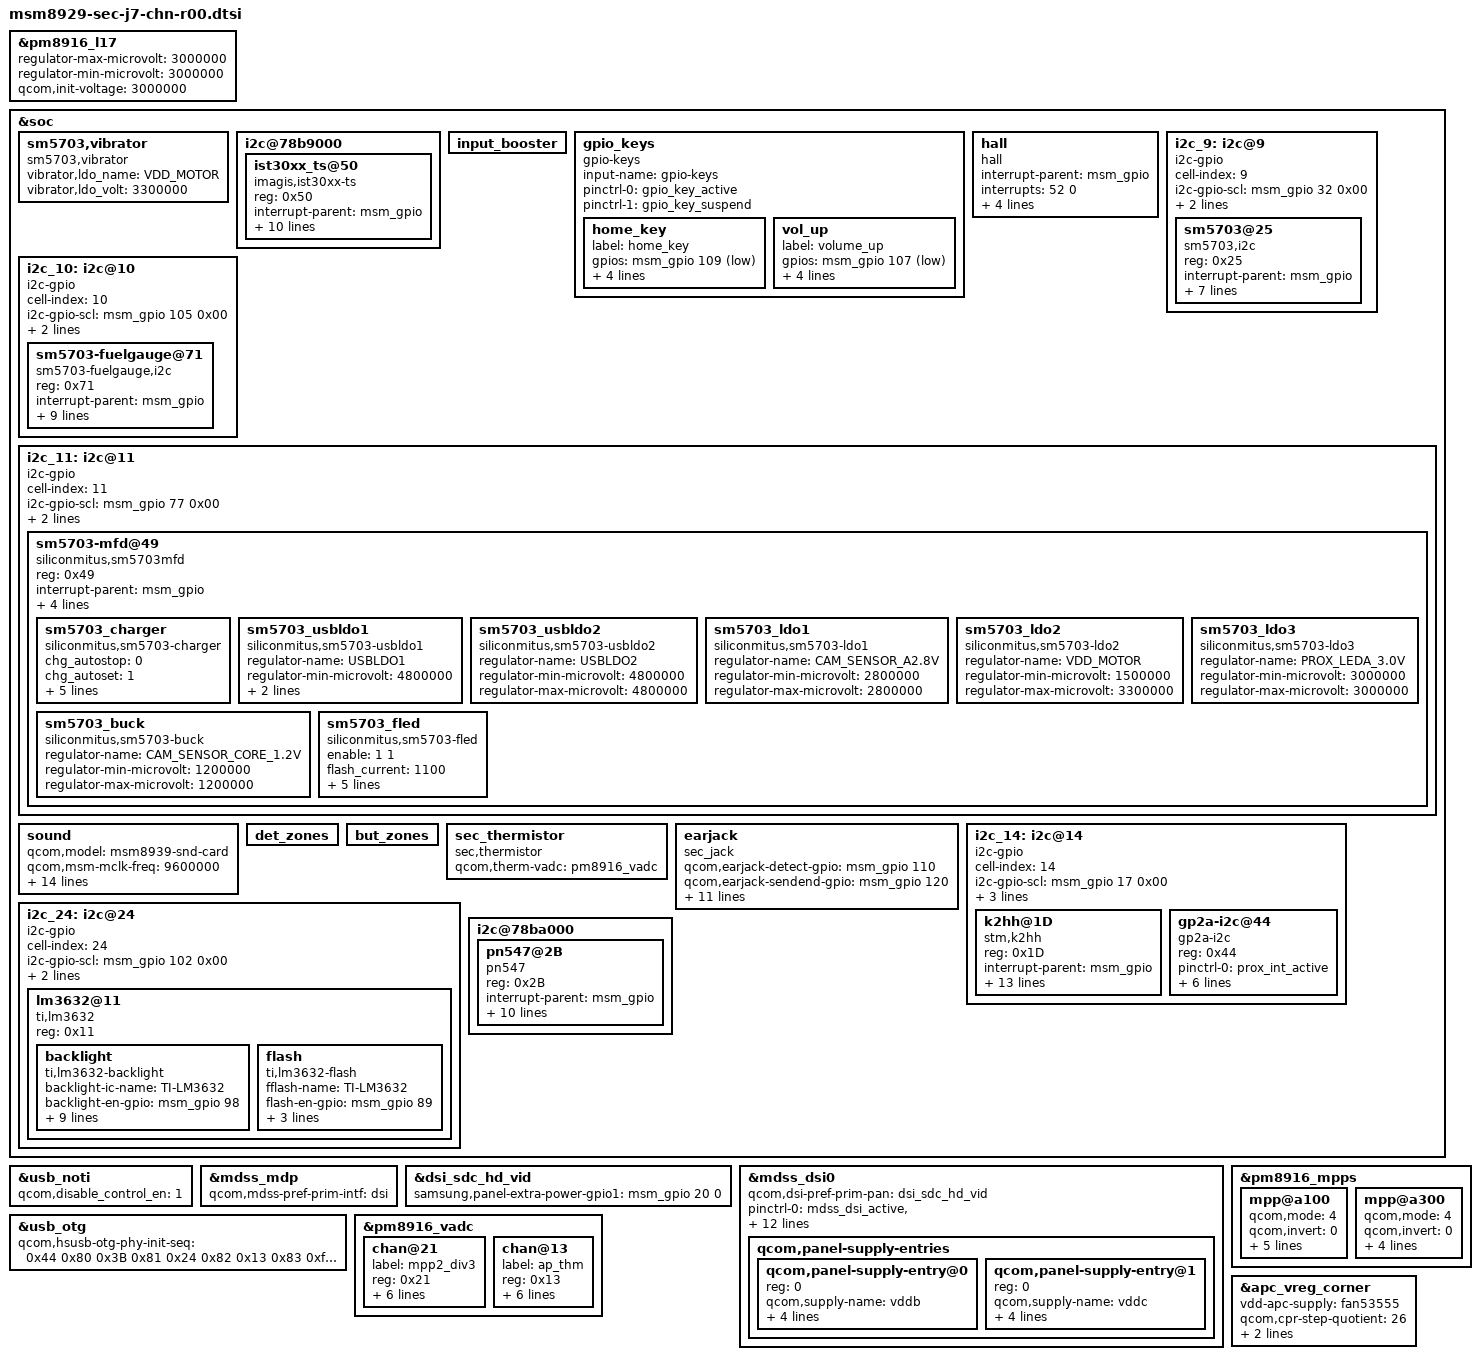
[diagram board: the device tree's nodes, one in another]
/*
 * Copyright (c) 2015, The Linux Foundation. All rights reserved.
 *
 * This program is free software; you can redistribute it and/or modify
 * it under the terms of the GNU General Public License version 2 and
 * only version 2 as published by the Free Software Foundation.
 *
 * This program is distributed in the hope that it will be useful,
 * but WITHOUT ANY WARRANTY; without even the implied warranty of
 * MERCHANTABILITY or FITNESS FOR A PARTICULAR PURPOSE.  See the
 * GNU General Public License for more details.
 */

#include "msm8929.dtsi"
#include "msm8929-pinctrl-sec-j7-chn-r00.dtsi"
#include "msm8939-cdp.dtsi"
#include "msm8939-mdss.dtsi"
#include "msm8929-sec-j7-battery-r00.dtsi"
#include "msm8939-audio-internal_codec.dtsi"
#include "../../../../../../drivers/video/msm/mdss/samsung/S6D7AA0X62_BV050HDM/dsi_panel_S6D7AA0X62_BV050HDM_hd_5_5_video.dtsi"
#include "msm8929-camera-sensor-cdp-j7-r00.dtsi"

&pm8916_l17 {
	regulator-max-microvolt = <3000000>;
	regulator-min-microvolt = <3000000>;
	qcom,init-voltage = <3000000>;
};

&soc {
	sm5703,vibrator {
		compatible = "sm5703,vibrator";
		vibrator,ldo_name = "VDD_MOTOR";
		vibrator,ldo_volt = <3300000>;
		status = "ok";
	};

	i2c@78b9000 { /* BLSP1 QUP5 */
		status = "okay";
		/delete-node/ synaptics@20;
		ist30xx_ts@50 {
			compatible = "imagis,ist30xx-ts";
			reg = <0x50>;
			interrupt-parent = <&msm_gpio>;
			interrupts = <13 0>;
			pinctrl-names = "active_state", "suspend_state";
			pinctrl-0 = <&ts_int_active &tsp_en_active>;
			pinctrl-1 = <&ts_int_suspend &tsp_en_suspend>;
			vdd_en-gpio = <&msm_gpio 73 0x01>;
			vdd_1p8-supply = <&pm8916_l6>;
			imagis,irq-gpio = <&msm_gpio 13 0x00>;
			imagis,i2c-pull-up = <1>;
			imagis,fw-bin = <1>;
			imagis,ic-version = "ist3038c";
			imagis,project-name = "j7";
		};
	};

	input_booster {
		status = "okay";
	};

	/delete-node/ gpio_keys;
	gpio_keys {
		compatible = "gpio-keys";
		input-name = "gpio-keys";
		pinctrl-names = "tlmm_gpio_key_active","tlmm_gpio_key_suspend";
		pinctrl-0 = <&gpio_key_active>;
		pinctrl-1 = <&gpio_key_suspend>;

		home_key {
			label = "home_key";
			gpios = <&msm_gpio 109 0x1>;
			linux,input-type = <1>;
			linux,code = <172>;
			gpio-key,wakeup;
			debounce-interval = <15>;
		};

		vol_up {
			label = "volume_up";
			gpios = <&msm_gpio 107 0x1>;
			linux,input-type = <1>;
			linux,code = <115>;
			gpio-key,wakeup;
			debounce-interval = <15>;
		};
	};

	 hall {
                status = "okay";
                compatible = "hall";
                interrupt-parent = <&msm_gpio>;
                interrupts = <52 0>;
                hall,gpio_flip_cover = <&msm_gpio 52 0>;
                hall_vdd-supply = <&pm8916_l5>;
                pinctrl-names = "flipcover_active","flipcover_suspend";
                pinctrl-0 = <&hall_int_active>;
                pinctrl-1 = <&hall_int_suspend>;
        };



	i2c_9:i2c@9 { /*SM5703 GPIO-I2C*/
		cell-index = <9>;
		compatible = "i2c-gpio";
		i2c-gpio-scl = <&msm_gpio 32 0x00>;
		i2c-gpio-sda = <&msm_gpio 31 0x00>;
		i2c-gpio,delay-us = <2>;
		#address-cells = <1>;
		#size-cells = <0>;

		sm5703@25{
			compatible = "sm5703,i2c";
			reg = <0x25>;
			interrupt-parent = <&msm_gpio>;
			interrupts= <12 0>;
			sm5703,irq-gpio = <&msm_gpio 12 0x00>;
			sm5703,gpio-scl = <&msm_gpio 32 0x00>;
			sm5703,gpio-sda = <&msm_gpio 31 0x00>;
			sm5703,uarton-gpio = <&msm_gpio 114 0x00>;
			pinctrl-names = "sm5703_i2c_active","sm5703_i2c_suspend";
			pinctrl-0 = <&muic_i2c_active &muic_int_pin>;
			pinctrl-1 = <&muic_i2c_suspend &muic_int_pin>;
		};
	};

	i2c_10:i2c@10 {
		cell-index = <10>;
		compatible = "i2c-gpio";
		i2c-gpio-scl = <&msm_gpio 105 0x00>;
		i2c-gpio-sda = <&msm_gpio 106 0x00>;
		i2c-gpio,delay-us = <2>;
		#address-cells = <1>;
		#size-cells = <0>;

		sm5703-fuelgauge@71{
			compatible = "sm5703-fuelgauge,i2c";
			reg = <0x71>;
			interrupt-parent = <&msm_gpio>;
			pinctrl-names = "default";
			pinctrl-0 = <&fg_i2c_active &fuel_int_active>;
			fuelgauge,irqf = "IRQF_TRIGGER_FALLING + IRQF_ONESHOT + IRQF_NO_SUSPEND";
			fuelgauge,fuel_int = <&msm_gpio 121 0x1>;
			fuelgauge,capacity_max = <1000>;
			fuelgauge,capacity_max_margin = <50>;
			fuelgauge,capacity_min = <0>;
			fuelgauge,capacity_calculation_type = <0x17>;
			fuelgauge,fuel_alert_soc = <1>;
		};
	};

	i2c_11:i2c@11 {
		cell-index = <11>;
		compatible = "i2c-gpio";
		i2c-gpio-scl = <&msm_gpio 77 0x00>;
		i2c-gpio-sda = <&msm_gpio 76 0x00>;
		i2c-gpio,delay-us = <2>;
		#address-cells = <1>;
		#size-cells = <0>;

		sm5703-mfd@49{
			compatible = "siliconmitus,sm5703mfd";
			reg = <0x49>;
			interrupt-parent = <&msm_gpio>;
			sm5703,irq-gpio = <&msm_gpio 62 0x00>;
			pinctrl-names = "default";
			pinctrl-0 = <&chg_i2c_active &charger_int_active &if_pmic_rst_active &chg_en_active>;
			sm5703,mrstb-gpio = <&msm_gpio 108 0x00>;

			sm5703_charger {
				compatible = "siliconmitus,sm5703-charger";
				chg_autostop = <0>;
				chg_autoset = <1>;
				chg_aiclen = <1>;
				chg_aiclth = <4500>;
				fg_vol_val = <4350>;
				fg_soc_val = <95>;
				fg_curr_avr_val = <150>;
			};

			sm5703_usbldo1 {
				compatible = "siliconmitus,sm5703-usbldo1";
				regulator-name = "USBLDO1"; /* change name by yourself */
				regulator-min-microvolt = <4800000>;
				regulator-max-microvolt = <4800000>; /* max == min then apply_uV = 1 */
				/* regulator-microvolt-offset = < >; optional*/
				/* regulator-boot-on = "yes"; optional, exist = enabled */
				regulator-always-on = "yes";
				/* regulator-ramp-delay = <100>; optional*/

			};
			sm5703_usbldo2 {
				compatible = "siliconmitus,sm5703-usbldo2";
				regulator-name = "USBLDO2"; /* change name by yourself */
				regulator-min-microvolt = <4800000>;
				regulator-max-microvolt = <4800000>; /* max == min then apply_uV = 1 */
				/* regulator-microvolt-offset = < >; optional*/
				/* regulator-boot-on = "yes"; optional, exist = enabled */
				/* regulator-always-on = "yes"; optional, exist = enabled */
				/* regulator-ramp-delay = <100>; optional*/

			};
			sm5703_ldo1 {
				compatible = "siliconmitus,sm5703-ldo1";
				regulator-name = "CAM_SENSOR_A2.8V"; /* change name by yourself */
				regulator-min-microvolt = <2800000>;
				regulator-max-microvolt = <2800000>; /* max == min then apply_uV = 1 */
				/* regulator-microvolt-offset = < >; optional*/
				/* regulator-boot-on = "yes"; optional, exist = enabled */
				/* regulator-always-on = "yes"; optional, exist = enabled */
				/* regulator-ramp-delay = <100>; optional*/
			};

			sm5703_ldo2 {
				compatible = "siliconmitus,sm5703-ldo2";
				regulator-name = "VDD_MOTOR"; /* change name by yourself */
				regulator-min-microvolt = <1500000>;
				regulator-max-microvolt = <3300000>; /* max == min then apply_uV = 1 */
				/* regulator-microvolt-offset = < >; optional*/
				/* regulator-boot-on = "yes"; optional, exist = enabled */
				/* regulator-always-on = "yes"; optional, exist = enabled */
				/* regulator-ramp-delay = <100>; optional*/
			};

			sm5703_ldo3 {
				compatible = "siliconmitus,sm5703-ldo3";
				regulator-name = "PROX_LEDA_3.0V"; /* change name by yourself */
				regulator-min-microvolt = <3000000>;
				regulator-max-microvolt = <3000000>; /* max == min then apply_uV = 1 */
				/* regulator-microvolt-offset = < >; optional*/
				/* regulator-boot-on = "yes"; optional, exist = enabled */
				/* regulator-always-on = "yes"; optional, exist = enabled */
				/* regulator-ramp-delay = <100>; optional*/
			};

			sm5703_buck {
				compatible = "siliconmitus,sm5703-buck";
				regulator-name = "CAM_SENSOR_CORE_1.2V"; /* change name by yourself */
				regulator-min-microvolt = <1200000>;
				regulator-max-microvolt = <1200000>; /* max == min then apply_uV = 1 */
				/* regulator-microvolt-offset = < >; optional*/
				/* regulator-boot-on = "yes"; optional, exist = enabled */
				/* regulator-always-on = "yes"; optional, exist = enabled */
				/* regulator-ramp-delay = <100>; optional*/
			};

			sm5703_fled {
				compatible = "siliconmitus,sm5703-fled";
				enable = <1 1>;
				flash_current = <1100>;
				movie_current = <200>;
				sm5703,led1-gpio = <&msm_gpio 34 0x00>;
				sm5703,led2-gpio = <&msm_gpio 36 0x00>;
				pinctrl-names = "fled_default","fled_sleep";
				pinctrl-0 = <&cam_flash_active>;
				pinctrl-1 = <&cam_flash_sleep>;
			};
		};
	};

	sound {
		qcom,model = "msm8939-snd-card";
/*		qcom,msm-ext-pa = "quaternary";*/
		qcom,msm-mclk-freq = <9600000>;
		qcom,audio-routing =
			"RX_BIAS", "MCLK",
			"SPK_RX_BIAS", "MCLK",
			"INT_LDO_H", "MCLK",
			"MIC BIAS External", "Handset Mic",
			"MIC BIAS External", "Secondary Mic",
			"AMIC1", "MIC BIAS External",
			"AMIC2", "Headset Mic",
			"AMIC3", "MIC BIAS External";
		pinctrl-names = "cdc_lines_act",
				"cdc_lines_sus",
				"cross_conn_det_act",
				"cross_conn_det_sus",
				"cdc_lines_quat_ext_act",
				"cdc_lines_quat_ext_sus";
		pinctrl-0 = <&cdc_pdm_lines_act>;
		pinctrl-1 = <&cdc_pdm_lines_sus>;
		pinctrl-2 = <&cross_conn_det_act>;
		pinctrl-3 = <&cross_conn_det_sus>;
		pinctrl-4 = <&cdc_pdm_lines_act &ext_cdc_tlmm_lines_act>;
		pinctrl-5 = <&cdc_pdm_lines_sus &ext_cdc_tlmm_lines_sus>;
	};

	det_zones: det_zones {
		#list-det-cells = <4>;
	};

	but_zones: but_zones {
		#list-but-cells = <3>;
	};

	sec_thermistor {
		compatible = "sec,thermistor";
		qcom,therm-vadc = <&pm8916_vadc>;
	};

	earjack {
		compatible = "sec_jack";
		qcom,earjack-detect-gpio = <&msm_gpio 110 0x0>;
		qcom,earjack-sendend-gpio = <&msm_gpio 120 0x0>;
		qcom,earjack-read-vadc = <&pm8916_vadc>;

		det-zones-list = <&det_zones 0 10000 10 0>,
						 <&det_zones 970 10000 10 0>,
						 <&det_zones 971 10000 10 1>,
						 <&det_zones 9999 10000 10 1>;
		but-zones-list = <&but_zones 0 0 302>,
						<&but_zones 3 303 349>,	
						 <&but_zones 1 350 462>,
						 <&but_zones 2 463 999>;
		mpp-channel-scaling = <2 1 3>;
		pinctrl-names = "earjack_gpio_active","earjack_gpio_suspend";
		pinctrl-0 = <&earjack_det_act &earjack_switch_act>;
		pinctrl-1 = <&earjack_det_sus &earjack_switch_sus>;
	};

	i2c_14:i2c@14 {
		cell-index = <14>;
		compatible = "i2c-gpio";
		i2c-gpio-scl = <&msm_gpio 17 0x00>;
		i2c-gpio-sda = <&msm_gpio 16 0x00>;
		i2c-gpio,delay-us = <2>;
		#address-cells = <1>;
		#size-cells = <0>;
		pinctrl-names = "default";
		pinctrl-0 = <&sensor_i2c_default>;
		k2hh@1D {
			compatible = "stm,k2hh";
			reg = <0x1D>;
			interrupt-parent = <&msm_gpio>;
			interrupts = <115 0>;
			pinctrl-names = "default";
			pinctrl-0 = <&acc_int_active>;
			stm,irq_gpio = <&msm_gpio 115 0x00>;
			stm,vio-supply = <&pm8916_l5>;
			stm,vdd-supply = <&pm8916_l17>;
			stm,axis_map_x = <0>;
			stm,axis_map_y = <1>;
			stm,axis_map_z = <2>;
			stm,negate_x = <0>;
			stm,negate_y = <0>;
			stm,negate_z = <1>;
			stm,poll_interval = <100>;
			stm,min_interval = <2>;
		};
		gp2a-i2c@44{
			compatible = "gp2a-i2c";
			reg = <0x44>;
			pinctrl-names = "default";
			pinctrl-0 = <&prox_int_active>;
			pinctrl-1 = <&prox_int_suspend>;
			interrupt-parent = <&msm_gpio>;
			interupts= <113 0>;
			gp2a-i2c,irq-gpio = <&msm_gpio 113 0x00>;
			gp2a-vdd-supply = <&pm8916_l17>;
			gp2a-vio-supply = <&pm8916_l5>;
		};
	};
};

&usb_noti {
	qcom,disable_control_en = <1>;
};

&mdss_mdp {
       qcom,mdss-pref-prim-intf = "dsi";
};

&dsi_sdc_hd_vid{
	samsung,panel-extra-power-gpio1 = <&msm_gpio 20 0>;
};

&mdss_dsi0 {
	qcom,dsi-pref-prim-pan = <&dsi_sdc_hd_vid>;
	pinctrl-names = "mdss_default", "mdss_sleep";
	pinctrl-0 = <&mdss_dsi_active &lcd_esd_det_active &bl_active &bl_i2c_active>;
	pinctrl-1 = <&mdss_dsi_suspend &lcd_esd_det_suspend &bl_suspend &bl_i2c_suspend>;
	qcom,platform-reset-gpio = <&msm_gpio 25 0>;
	gdsc-supply = <&gdsc_mdss>;
	vddb-supply = <&pm8916_s4>;
	vddc-supply = <&pm8916_l5>;
	qcom,platform-regulator-settings = [07 09 03 00 20 00 01];
	qcom,platform-lane-config = [00 00 00 00 00 00 00 01 97
		00 00 00 00 05 00 00 01 97
		00 00 00 00 0a 00 00 01 97
		00 00 00 00 0f 00 00 01 97
		00 c0 00 00 00 00 00 01 bb];
	qcom,panel-supply-entries {
		#address-cells = <1>;
		#size-cells = <0>;

		qcom,panel-supply-entry@0 {
			reg = <0>;
			qcom,supply-name = "vddb";
			qcom,supply-min-voltage = <2100000>;
			qcom,supply-max-voltage = <2100000>;
			qcom,supply-enable-load = <100000>;
			qcom,supply-disable-load = <100>;
		};
		qcom,panel-supply-entry@1 {
			reg = <0>;
			qcom,supply-name = "vddc";
			qcom,supply-min-voltage = <1800000>;
			qcom,supply-max-voltage = <1800000>;
			qcom,supply-enable-load = <100000>;
			qcom,supply-disable-load = <100>;
		};
	};
};

&pm8916_mpps {
	mpp@a100 { /* MPP 2 */
		status = "ok";
		qcom,mode = <4>; // AIN input
		qcom,invert = <0>; //No Invert
		qcom,output-type = <0>; //CMOS
		qcom,vin-sel = <2>; //PM8971_S3 1.8v
		qcom,src-sel = <0>; //MPP Constant
		qcom,ain-route = <1>; // QPNP_PIN_AIN_AMUX_CH6 = 1 for MPP2
		qcom,master-en = <1>; // Function constant
	};
	mpp@a300 { /* MPP 4 */
		status = "ok";
		qcom,mode = <4>;	/* AIN input */
		qcom,invert = <0>;	/* No Invert */
		qcom,output-type = <0>;	/* CMOS */
		qcom,src-sel = <0>;	/* MPP Constant */
		qcom,ain-route = <3>;	/* QPNP_PIN_AIN_AMUX_CH8 = 3 for MPP4 */
		qcom,master-en = <1>;	/* Function constant */
	};
};

&usb_otg {
        qcom,hsusb-otg-phy-init-seq =
                        <0x44 0x80 0x3B 0x81 0x24 0x82 0x13 0x83 0xffffffff>;
};

&pm8916_vadc {
	chan@21 {
		label = "mpp2_div3";
		reg = <0x21>; // channel for MPP2 , 1:3scale
		qcom,decimation = <0>;
		qcom,pre-div-channel-scaling = <1>; // 1:3scale
		qcom,calibration-type = "absolute";
		qcom,scale-function = <0>;
		qcom,hw-settle-time = <1>;
		qcom,fast-avg-setup = <0>;
	};
};

&soc {
	i2c_24: i2c@24 {

		cell-index = <24>;
		compatible = "i2c-gpio";
		i2c-gpio-scl = <&msm_gpio 102  0x00>; /*scl gpio*/
		i2c-gpio-sda = <&msm_gpio 101 0x00>;  /*sda gpio*/
		i2c-gpio,delay-us = <4>;
		lm3632@11 {
			compatible = "ti,lm3632";
			reg = <0x11>;
			backlight{
				compatible = "ti,lm3632-backlight";
				backlight-ic-name = "TI-LM3632";
				backlight-en-gpio = <&msm_gpio 98 0x00>;
				backlight-panel-enp-gpio = <&msm_gpio 50 0x00>;
				backlight-panel-enn-gpio = <&msm_gpio 51 0x00>;
				backlight-ic-tuning = [
					09	41
					02	50
					03	0D
					04	05
					0A	19
					05	CC
					0D	1E
					0E	1E
					0F	1E
					0C	1F
				];
				backlight-ic-tuning-outdoor = [
					09	01
					04	06
					05	D1
				];
				backlight-ic-tuning-normal = [
					04	05
					05	CC
					09	41
				];
				backlight-i2c-bl-control = [
					04      00
					05      00
				];
			};
			flash{
				compatible = "ti,lm3632-flash";
				fflash-name = "TI-LM3632";
				flash-en-gpio = <&msm_gpio 89 0x00>;
				flash-int-gpio = <&msm_gpio 90 0x00>;
				pinctrl-names = "front_fled_default","front_fled_sleep";
				pinctrl-0 = <&front_flash_active>;
				pinctrl-1 = <&front_flash_sleep>;
			};
		};
	};
};

&apc_vreg_corner {
	vdd-apc-supply = <&fan53555>;
	qcom,cpr-step-quotient = <26>;
	qcom,cpr-apc-volt-step = <12500>;
	qcom,cpr-up-threshold = <2>;
};

&soc {
	i2c@78ba000 { /* BLSP1 QUP6 */
		status = "ok";
		pn547@2B {
			compatible = "pn547";
			reg = <0x2B>;
			interrupt-parent = <&msm_gpio>;
			interrupts = <21 0>;
			pinctrl-names = "nfc_active","nfc_suspend";
			pinctrl-0 = <&nfc_int_active &nfc_enable_active &nfc_firmware_active>;
			pinctrl-1 = <&nfc_int_suspend &nfc_enable_suspend &nfc_firmware_suspend>;
			pn547,firm-gpio = <&msm_gpio 49 0x00>;
			pn547,ven-gpio = <&msm_gpio 116 0x00>;
			pn547,irq-gpio = <&msm_gpio 21 0x01>;
			nfc_ldo-supply = <&pm8916_l14>;
			clocks = <&clock_rpm clk_bb_clk2>;
			clock-names = "nfc_clock";
		};
	};
};
&pm8916_vadc {
	chan@13 {
		label = "ap_thm";
		reg = <0x13>;	/* channel 19 for MPP4 , 1:1scale */
		qcom,decimation = <0>;
		qcom,pre-div-channel-scaling = <0>;	/* 1:1scale */
		qcom,calibration-type = "ratiometric";
		qcom,scale-function = <1>;
		qcom,hw-settle-time = <2>;
		qcom,fast-avg-setup = <0>;
	};
};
